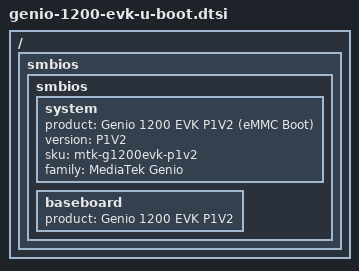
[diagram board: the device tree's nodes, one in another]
// SPDX-License-Identifier: GPL-2.0 OR MIT
/*
 * Copyright (C) 2023 MediaTek Inc.
 * Author: Macpaul Lin <macpaul.lin@mediatek.com>
 */

#include "smbios.dtsi"

/ {
	smbios {
		smbios {
			system {
				product = "Genio 1200 EVK P1V2 (eMMC Boot)";
				version = "P1V2";
				sku = "mtk-g1200evk-p1v2";
				family = "MediaTek Genio";
			};
			baseboard {
				product = "Genio 1200 EVK P1V2";
			};
		};
	};
};
